AUTOSAR XML (schema 4-0-3)
package /ComponentTypes
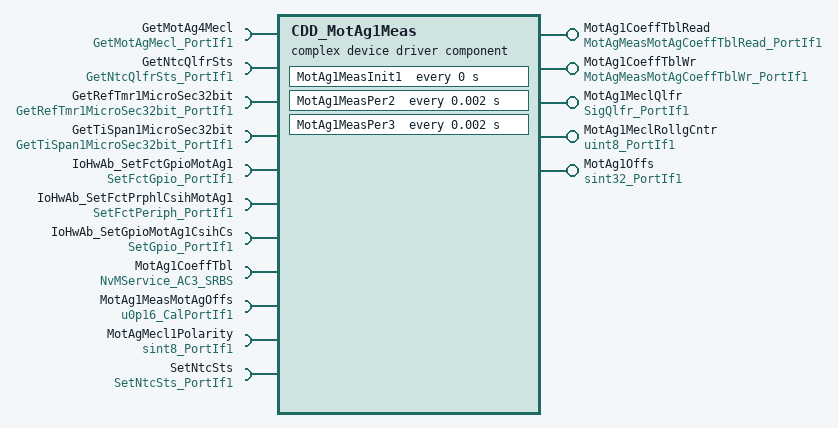
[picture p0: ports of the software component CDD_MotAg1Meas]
  complex device driver sw component type CDD_MotAg1Meas
    5 x provide port:
      MotAg1CoeffTblRead: server-com-spec{operation=Oper, queue-length=1}, provided-interface=MotAgMeasMotAgCoeffTblRead_PortIf1
      MotAg1CoeffTblWr: server-com-spec{operation=Oper, queue-length=1}, provided-interface=MotAgMeasMotAgCoeffTblWr_PortIf1
      MotAg1MeclQlfr: nonqueued-sender-com-spec{data-element=Val, init-value=0}, provided-interface=SigQlfr_PortIf1
      MotAg1MeclRollgCntr: nonqueued-sender-com-spec{data-element=Val, init-value=0}, provided-interface=uint8_PortIf1
      MotAg1Offs: nonqueued-sender-com-spec{data-element=Val, init-value=0}, provided-interface=sint32_PortIf1
    11 x require port:
      GetMotAg4Mecl: required-interface=GetMotAgMecl_PortIf1
      GetNtcQlfrSts: required-interface=GetNtcQlfrSts_PortIf1
      GetRefTmr1MicroSec32bit: required-interface=GetRefTmr1MicroSec32bit_PortIf1
      GetTiSpan1MicroSec32bit: required-interface=GetTiSpan1MicroSec32bit_PortIf1
      IoHwAb_SetFctGpioMotAg1: required-interface=SetFctGpio_PortIf1
      IoHwAb_SetFctPrphlCsihMotAg1: required-interface=SetFctPeriph_PortIf1
      IoHwAb_SetGpioMotAg1CsihCs: required-interface=SetGpio_PortIf1
      MotAg1CoeffTbl: required-interface=NvMService_AC3_SRBS
      MotAg1MeasMotAgOffs: parameter-require-com-spec{init-value=32768, parameter=Val}, required-interface=u0p16_CalPortIf1
      MotAgMecl1Polarity: nonqueued-receiver-com-spec{data-element=Val, filter=data-filter-type=ALWAYS, init-value=1}, required-interface=sint8_PortIf1
      SetNtcSts: required-interface=SetNtcSts_PortIf1
    behavior CDD_MotAg1Meas_InternalBehavior: data-type-mapping=Nexteer
      ar-typed-per-instance-memorys:
        17 x data, all with sw-calibration-access=READ-ONLY:
          dMotAg1MeasMotAg1Delta: type=u0p16
          dMotAg1MeasMotAg1RawAgReg: type=uint32
          dMotAg1MeasMotAg1RawErrReg: type=uint32
          dMotAg1MeasMotAg1RawReg: type=Ary1D_u32_10
          dMotAg1MeasMotAg1RawTurnCntrReg: type=uint32
          dMotAg1MeasMotAg1RtOffs: type=sint32
          dMotAg1MeasMotAg1SpiCntrAg: type=u0p16
          dMotAg1MeasMotAg1SpiMecl: type=u0p16
          dMotAg1MeasMotAg1TurnCntr: type=float32
          dMotAg1MeasMotCtrlMotAg4Mecl: type=u0p16
          MotAg1CoeffTbl: type=Ary1D_f32_26
          MotAg1CorrnTbl: type=Ary1D_sm5p12_128
          MotAg1Diagc: type=u0p16
          MotAg1InitOffs: type=uint8
          MotAg1PrevOffs: type=sint32
          MotAg1PrevRollgCntr: type=uint8
          MotAg1PrevSpiErrFltCntr: type=uint16
      operation invoked event OIT_MotAg1CoeffTblRead_Oper_MotAg1CoeffTblRead_Oper: start-on-event=MotAg1CoeffTblRead_Oper, operation=MotAg1CoeffTblRead.Oper
      operation invoked event OIT_MotAg1CoeffTblWr_Oper_MotAg1CoeffTblWr_Oper: start-on-event=MotAg1CoeffTblWr_Oper, operation=MotAg1CoeffTblWr.Oper
      timing event MotAg1MeasInit1_InitEvent: start-on-event=MotAg1MeasInit1, period=0
      timing event TMT_MotAg0MeasPer2: start-on-event=MotAg1MeasPer2, period=0.002
      timing event TMT_MotAg1MeasPer3: start-on-event=MotAg1MeasPer3, period=0.002
      explicit-inter-runnable-variables:
        data MotAg1DiagcAg: type=u0p16, init-value=0
        data MotAg1SpiTrsmEna: type=boolean, init-value=0
        data MotAg4Mecl: type=u0p16, init-value=0
      5 x runnable:
        MotAg1CoeffTblRead_Oper
        MotAg1CoeffTblWr_Oper
          sync call SC_MotAg1CoeffTbl_SetRamBlockStatus: operation=MotAg1CoeffTbl.SetRamBlockStatus, timeout=0
        MotAg1MeasInit1
          sync call SC_MotAg1CoeffTbl_GetErrorStatus: operation=MotAg1CoeffTbl.GetErrorStatus, timeout=0
          sync call SC_MotAg1CoeffTbl_GetErrorStatus_1: operation=MotAg1CoeffTbl.GetErrorStatus, timeout=0
        MotAg1MeasPer2
          data-receive-point-by-arguments:
            access REC_MotAgMecl0Polarity_Val: accessed-variable=MotAgMecl1Polarity.Val
          data-send-points:
            access SEND_MotAg0MeclRollgCntr_Val: accessed-variable=MotAg1MeclRollgCntr.Val
            access SEND_MotAg0Offs_Val: accessed-variable=MotAg1Offs.Val
            access SEND_MotAg1MeclQlfr_Val: accessed-variable=MotAg1MeclQlfr.Val
          read-local-variables:
            access READ_MotAg1DiagcAg: accessed-variable=MotAg1DiagcAg
            access READ_MotAg1SpiTrsmEna: accessed-variable=MotAg1SpiTrsmEna
            access READ_MotAg4Mecl: accessed-variable=MotAg4Mecl
          sync call SC_GetNtcQlfrSts_Oper: operation=GetNtcQlfrSts.Oper, timeout=0
          sync call SC_SetNtcSts_Oper: operation=SetNtcSts.Oper, timeout=0
        MotAg1MeasPer3
          6 x sync call, all with timeout=0:
            SC_GetMotAgMecl_Oper: operation=GetMotAg4Mecl.Oper
            SC_GetRefTmr1MicroSec32bit_Oper: operation=GetRefTmr1MicroSec32bit.Oper
            SC_GetTiSpan1MicroSec32bit_Oper: operation=GetTiSpan1MicroSec32bit.Oper
            SC_IoHwAb_SetFctGpioMotAg1_Oper: operation=IoHwAb_SetFctGpioMotAg1.Oper
            SC_IoHwAb_SetFctPrphlCsihMotAg0_Oper: operation=IoHwAb_SetFctPrphlCsihMotAg1.Oper
            SC_IoHwAb_SetGpioMotAg1CsihCs_Oper: operation=IoHwAb_SetGpioMotAg1CsihCs.Oper
          written-local-variables:
            access WRITE_MotAg1DiagcAg: accessed-variable=MotAg1DiagcAg
            access WRITE_MotAg1SpiTrsmEna: accessed-variable=MotAg1SpiTrsmEna
            access WRITE_MotAg4Mecl: accessed-variable=MotAg4Mecl
      swc service dependency NvmMotAg1CoeffTbl
        assigned-datas:
          role=ramBlock, used-data-element=MotAg1CoeffTbl
          role=defaultValue, used-parameter-element=MotAg1CoeffTblDft
        assigned-ports:
          port-prototype=MotAg1CoeffTbl, role=NvMService_AC3_SRBS
          port-prototype=MotAg1CoeffTbl, role=NvMService_AC3_SRBS
        service-needs:
          nv block needs NvmMotAg1CoeffTbl: n-data-sets=0, readonly=false, reliability=ERROR-DETECTION, resistant-to-changed-sw=true, restore-at-start=true, store-at-shutdown=true, write-only-once=false, writing-frequency=0, writing-priority=LOW
      shared-parameters:
        parameter data prototype MotAg1CoeffTblDft: sw-calibration-access=READ-WRITE, type=Ary1D_f32_26, init-value=26 x 0
  swc implementation CDD_MotAg1Meas_Implementation: behavior=CDD_MotAg1Meas_InternalBehavior
    code-descriptors:
      code Default: artifact-descriptors=autosar-engineering-object={short-label=Default, category=SWSRC}
